AUTOSAR XML (schema 4-0-3)
package /ComponentTypes
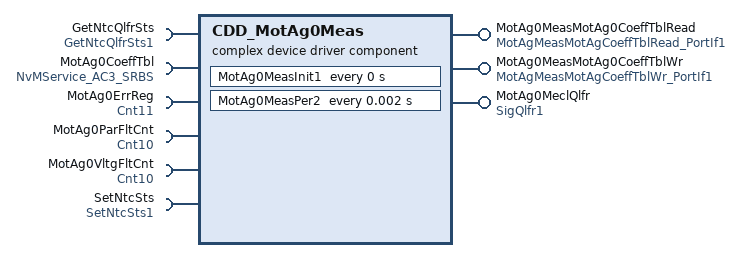
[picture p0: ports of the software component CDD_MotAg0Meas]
  complex device driver sw component type CDD_MotAg0Meas
    provide port MotAg0MeasMotAg0CoeffTblRead: server-com-spec{operation=Oper, queue-length=1}, provided-interface=MotAgMeasMotAgCoeffTblRead_PortIf1
    provide port MotAg0MeasMotAg0CoeffTblWr: server-com-spec{operation=Oper, queue-length=1}, provided-interface=MotAgMeasMotAgCoeffTblWr_PortIf1
    provide port MotAg0MeclQlfr: nonqueued-sender-com-spec{data-element=Val, init-value=0}, provided-interface=SigQlfr1
    6 x require port:
      GetNtcQlfrSts: required-interface=GetNtcQlfrSts1
      MotAg0CoeffTbl: required-interface=NvMService_AC3_SRBS
      MotAg0ErrReg: nonqueued-receiver-com-spec{data-element=Val, filter=data-filter-type=ALWAYS, init-value=0}, required-interface=Cnt11
      MotAg0ParFltCnt: nonqueued-receiver-com-spec{data-element=Val, filter=data-filter-type=ALWAYS, init-value=0}, required-interface=Cnt10
      MotAg0VltgFltCnt: nonqueued-receiver-com-spec{data-element=Val, filter=data-filter-type=ALWAYS, init-value=0}, required-interface=Cnt10
      SetNtcSts: required-interface=SetNtcSts1
    behavior CDD_MotAg0Meas_InternalBehavior: data-type-mapping=Nexteer
      ar-typed-per-instance-memorys:
        14 x data, all with sw-calibration-access=READ-ONLY:
          dMotAg0MeasMotAg0RawAgReg: type=Cnt17
          dMotAg0MeasMotAg0RawErrReg: type=Cnt17
          dMotAg0MeasMotAg0RawTurnCntrReg: type=Cnt17
          MotAg0CoeffTbl: type=Ary1D_f32_26
          MotAg0CorrnTbl: type=Ary1D_sm5p12_128
          MotAg0ErrParFltCntPrev: type=Cnt16
          MotAg0ErrParFltNtcStInfoCntPrev: type=Cnt16
          MotAg0ErrPrev: type=Cnt18
          MotAg0MeclRollgCntrPrev: type=Cnt19
          MotAg0ParFltCntPrev: type=Cnt16
          MotAg0ParFltNtcStInfoCntPrev: type=Cnt16
          MotAg0RawMeclPrev: type=Ag5
          MotAg0VltgFltCntPrev: type=Cnt16
          MotAg0VltgFltNtcStInfoCntPrev: type=Cnt16
      timing event CDD_MotAg0Meas_InitEvent: start-on-event=MotAg0MeasInit1, period=0
      operation invoked event OIT_MotAg0MeasMotAg0CoeffTblRead_Oper_MotAg0MeasMotAg0CoeffTblRead_Oper: start-on-event=MotAg0MeasMotAg0CoeffTblRead_Oper, operation=MotAg0MeasMotAg0CoeffTblRead.Oper
      operation invoked event OIT_MotAg0MeasMotAg0CoeffTblWr_Oper_MotAg0MeasMotAg0CoeffTblWr_Oper: start-on-event=MotAg0MeasMotAg0CoeffTblWr_Oper, operation=MotAg0MeasMotAg0CoeffTblWr.Oper
      timing event TMT_MotAg0MeasPer2: start-on-event=MotAg0MeasPer2, period=0.002
      4 x runnable:
        MotAg0MeasInit1
          sync call SC_MotAg0CoeffTbl_GetErrorStatus_1: operation=MotAg0CoeffTbl.GetErrorStatus, timeout=0
        MotAg0MeasMotAg0CoeffTblRead_Oper
        MotAg0MeasMotAg0CoeffTblWr_Oper
          sync call SC_MotAg0CoeffTbl_SetRamBlockStatus_1: operation=MotAg0CoeffTbl.SetRamBlockStatus, timeout=0
        MotAg0MeasPer2
          data-receive-point-by-arguments:
            access REC_MotAg0ErrReg_Val: accessed-variable=MotAg0ErrReg.Val
            access REC_MotAg0ParFltCnt_Val: accessed-variable=MotAg0ParFltCnt.Val
            access REC_MotAg0VltgFltCnt_Val: accessed-variable=MotAg0VltgFltCnt.Val
          data-send-points:
            access SEND_MotAg0MeclQlfr_Val: accessed-variable=MotAg0MeclQlfr.Val
          sync call SC_GetNtcQlfrSts_Oper: operation=GetNtcQlfrSts.Oper, timeout=0
          sync call SC_SetNtcSts_Oper: operation=SetNtcSts.Oper, timeout=0
      swc service dependency NvmMotAg0CoeffTbl
        assigned-datas:
          role=ramBlock, used-data-element=MotAg0CoeffTbl
          role=defaultValue, used-parameter-element=MotAg0CoeffTblDft
        assigned-ports:
          port-prototype=MotAg0CoeffTbl, role=NvMService_AC3_SRBS
          port-prototype=MotAg0CoeffTbl, role=NvMService_AC3_SRBS
        service-needs:
          nv block needs NvmMotAg0CoeffTbl: n-data-sets=0, readonly=false, reliability=ERROR-DETECTION, resistant-to-changed-sw=true, restore-at-start=true, store-at-shutdown=true, write-only-once=false, writing-frequency=0, writing-priority=LOW
      shared-parameters:
        parameter data prototype MotAg0CoeffTblDft: sw-calibration-access=READ-WRITE, type=Ary1D_f32_26, init-value=26 x 0
  swc implementation CDD_MotAg0Meas_Implementation: behavior=CDD_MotAg0Meas_InternalBehavior
    code-descriptors:
      code Default: artifact-descriptors=autosar-engineering-object={short-label=Default, category=SWSRC}
